# dm648_cslr_memprot_config_001 register map
Vendor: Texas Instruments
Peripheral module from a debugger description file.
Registers are 32-bit, access not given, reset 0x0 unless marked. A register's access mark holds for its fields unless they carry their own. Offsets are as the file gives them; lines under a group give offsets from that group; [hi:lo] are bit positions; {n}, {i} and the like mark numbered series; 'fields as' and 'values as' point back to an identical list; <NAME> marks a mode.

## MEMPROTCONFIG — Memory Protection for Config
0x00 MPFAR rw — Config Memory Protection Fault Address Reg
  [31:0] ADDR — Config Fault Address
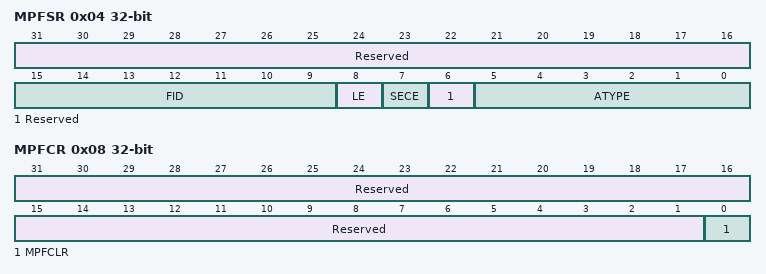
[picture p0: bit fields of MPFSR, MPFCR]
0x04 MPFSR — Config Memory Protection Fault Status Reg
  [31:16] Reserved — (access N)
  [15:9] FID — ID of Faulting Access (access RC)
    1=FAULT (Fault Occurred); 0=OK (No Fault Occurred)
  [8] LE — Fault Due to Local Access (access RC)
  [7] SECE — Security Error (access RC)
    1=FAULT (Fault Occurred); 0=OK (No Fault Occurred)
  [6] Reserved — (access N)
  [5:0] ATYPE — Fault Access Type (access RC)
0x08 MPFCR — Config Memory Fault Clear Register
  [31:1] Reserved — (access N)
  [0] MPFCLR wo — Set to clear fault
    1=CLEAR (Clears Fault)
